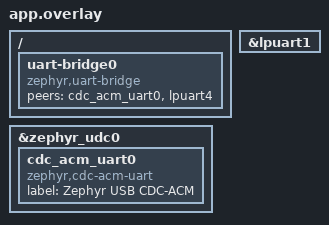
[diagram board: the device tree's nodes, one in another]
/*
 * Copyright 2025 Google LLC
 *
 * SPDX-License-Identifier: Apache-2.0
 */

/ {
	uart-bridge0 {
		compatible = "zephyr,uart-bridge";
		peers = <&cdc_acm_uart0 &lpuart4>;
	};

};

&lpuart1 {
	status = "okay";
};

&zephyr_udc0 {
	cdc_acm_uart0: cdc_acm_uart0 {
		compatible = "zephyr,cdc-acm-uart";
		label = "Zephyr USB CDC-ACM";
	};
};
